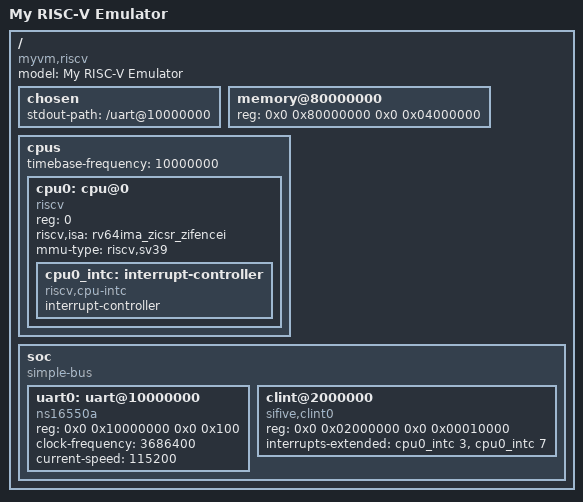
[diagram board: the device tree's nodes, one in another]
/dts-v1/;

/ {
    #address-cells = <2>;
    #size-cells = <2>;

    compatible = "myvm,riscv";
    model = "My RISC-V Emulator";

    chosen {
        stdout-path = "/uart@10000000";
    };

    memory@80000000 {
        device_type = "memory";
        reg = <0x0 0x80000000
               0x0 0x04000000>;
    };

    cpus {
        #address-cells = <1>;
        #size-cells = <0>;

        timebase-frequency = <10000000>;

        cpu0: cpu@0 {
            device_type = "cpu";
            reg = <0>;
            status = "okay";
            compatible = "riscv";

            riscv,isa = "rv64ima_zicsr_zifencei";
            mmu-type = "riscv,sv39";

            cpu0_intc: interrupt-controller {
                #interrupt-cells = <1>;
                interrupt-controller;
                compatible = "riscv,cpu-intc";
            };
        };
    };

    soc {
        #address-cells = <2>;
        #size-cells = <2>;

        compatible = "simple-bus";
        ranges;

        uart0: uart@10000000 {
            compatible = "ns16550a";

            reg = <0x0 0x10000000
                   0x0 0x100>;

            clock-frequency = <3686400>;
            current-speed = <115200>;
        };

        clint@2000000 {
            compatible = "sifive,clint0";

            reg = <0x0 0x02000000
                   0x0 0x00010000>;

            interrupts-extended =
                <&cpu0_intc 3>,
                <&cpu0_intc 7>;
        };
    };
};
